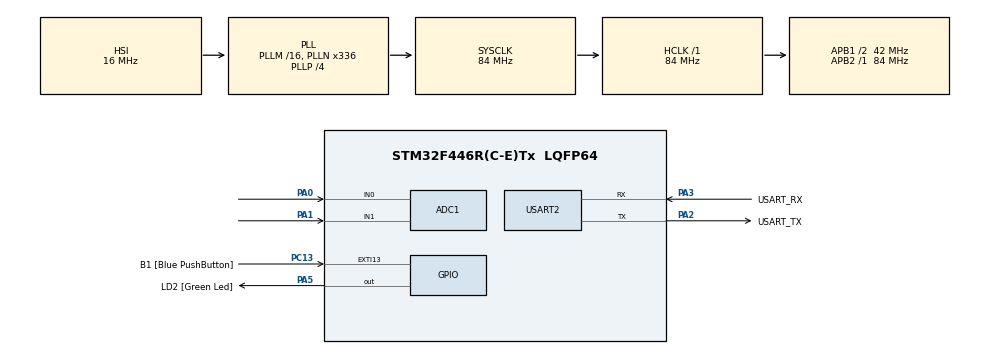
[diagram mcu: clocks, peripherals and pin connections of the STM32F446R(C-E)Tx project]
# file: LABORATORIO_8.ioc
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ADC1.Channel-0\#ChannelRegularConversion=ADC_CHANNEL_0
ADC1.Channel-1\#ChannelRegularConversion=ADC_CHANNEL_1
ADC1.ContinuousConvMode=ENABLE
ADC1.DMAContinuousRequests=ENABLE
ADC1.NbrOfConversion=2
ADC1.NbrOfConversionFlag=1
ADC1.Rank-0\#ChannelRegularConversion=1
ADC1.Rank-1\#ChannelRegularConversion=2
ADC1.SamplingTime-0\#ChannelRegularConversion=ADC_SAMPLETIME_3CYCLES
ADC1.SamplingTime-1\#ChannelRegularConversion=ADC_SAMPLETIME_3CYCLES
ADC1.ScanConvMode=ENABLE
ADC1.master=1
Dma.ADC1.0.Direction=DMA_PERIPH_TO_MEMORY
Dma.ADC1.0.FIFOMode=DMA_FIFOMODE_DISABLE
Dma.ADC1.0.Instance=DMA2_Stream0
Dma.ADC1.0.MemDataAlignment=DMA_MDATAALIGN_HALFWORD
Dma.ADC1.0.MemInc=DMA_MINC_ENABLE
Dma.ADC1.0.Mode=DMA_CIRCULAR
Dma.ADC1.0.PeriphDataAlignment=DMA_PDATAALIGN_HALFWORD
Dma.ADC1.0.PeriphInc=DMA_PINC_DISABLE
Dma.ADC1.0.Priority=DMA_PRIORITY_LOW
Dma.Request0=ADC1
Mcu.Family=STM32F4
Mcu.Name=STM32F446R(C-E)Tx
Mcu.Package=LQFP64
NVIC.ADC_IRQn=true\:0\:0\:false\:false\:true\:true\:true\:true
NVIC.DMA2_Stream0_IRQn=true\:0\:0\:false\:false\:true\:false\:true\:true
NVIC.PriorityGroup=NVIC_PRIORITYGROUP_0
NVIC.USART2_IRQn=true\:0\:0\:false\:false\:true\:true\:true\:true
PA0-WKUP.Signal=ADCx_IN0
PA1.Signal=ADCx_IN1
PA10.Signal=USART1_RX
PA13.GPIO_Label=TMS
PA13.Mode=Serial_Wire
PA13.Signal=SYS_JTMS-SWDIO
PA14.GPIO_Label=TCK
PA14.Mode=Serial_Wire
PA14.Signal=SYS_JTCK-SWCLK
PA2.GPIO_Label=USART_TX
PA2.Mode=Asynchronous
PA2.Signal=USART2_TX
PA3.GPIO_Label=USART_RX
PA3.Mode=Asynchronous
PA3.Signal=USART2_RX
PA5.GPIO_Label=LD2 [Green Led]
PA5.Signal=GPIO_Output
PA9.Signal=USART1_TX
PB3.GPIO_Label=SWO
PB3.Signal=SYS_JTDO-SWO
PC13.GPIO_Label=B1 [Blue PushButton]
PC13.GPIO_ModeDefaultEXTI=GPIO_MODE_IT_FALLING
PC13.Signal=GPXTI13
PC14-OSC32_IN.Mode=LSE-External-Oscillator
PC14-OSC32_IN.Signal=RCC_OSC32_IN
PC15-OSC32_OUT.Mode=LSE-External-Oscillator
PC15-OSC32_OUT.Signal=RCC_OSC32_OUT
PH0-OSC_IN.Mode=HSE-External-Oscillator
PH0-OSC_IN.Signal=RCC_OSC_IN
PH1-OSC_OUT.Mode=HSE-External-Oscillator
PH1-OSC_OUT.Signal=RCC_OSC_OUT
ProjectManager.HeapSize=0x200
ProjectManager.StackSize=0x400
ProjectManager.TargetToolchain=STM32CubeIDE
RCC.48MHZClocksFreq_Value=84000000
RCC.AHBFreq_Value=84000000
RCC.APB1CLKDivider=RCC_HCLK_DIV2
RCC.APB1Freq_Value=42000000
RCC.APB1TimFreq_Value=84000000
RCC.APB2Freq_Value=84000000
RCC.APB2TimFreq_Value=84000000
RCC.CortexFreq_Value=84000000
RCC.FLatency-AdvancedSettings=FLASH_LATENCY_2
RCC.HCLKFreq_Value=84000000
RCC.HSE_VALUE=8000000
RCC.HSI_VALUE=16000000
RCC.PLLN=336
RCC.PLLP=RCC_PLLP_DIV4
RCC.SYSCLKFreq_VALUE=84000000
RCC.SYSCLKSource=RCC_SYSCLKSOURCE_PLLCLK
RCC.USBFreq_Value=168000000
RCC.VCOOutputFreq_Value=336000000
SH.ADCx_IN0.0=ADC1_IN0,IN0
SH.ADCx_IN1.0=ADC1_IN1,IN1
USART2.VirtualMode=VM_ASYNC
board=NUCLEO-F446RE

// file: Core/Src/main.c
/* USER CODE BEGIN Header */
/**
  ******************************************************************************
  * @file           : main.c
  * @brief          : LABORATORIO 8 - Joystick Funcional
  ******************************************************************************
  */
/* USER CODE END Header */
#include "main.h"
#include <stdio.h>

/* Variables de Hardware */
ADC_HandleTypeDef hadc1;
UART_HandleTypeDef huart2;
DMA_HandleTypeDef hdma_adc1; // Variable fantasma para evitar errores de linker

/* USER CODE BEGIN PV */
volatile uint16_t ADC_VALOR[2] = {2048, 2048};
volatile uint8_t  canal_actual = 0;
/* USER CODE END PV */

/* Prototipos */
void SystemClock_Config(void);
static void MX_GPIO_Init(void);
static void MX_ADC1_Init(void);
static void MX_USART2_UART_Init(void);

/* Redireccion de printf */
int _write(int file, char *ptr, int len) {
    HAL_UART_Transmit(&huart2, (uint8_t*)ptr, len, HAL_MAX_DELAY);
    return len;
}

/**
  * @brief Callback de Interrupción: Guarda PA0 y luego PA1
  */
void HAL_ADC_ConvCpltCallback(ADC_HandleTypeDef* hadc) {
    if(hadc->Instance == ADC1) {
        ADC_VALOR[canal_actual] = HAL_ADC_GetValue(hadc);
        canal_actual = (canal_actual == 0) ? 1 : 0;
    }
}

int main(void) {
    HAL_Init();
    SystemClock_Config();
    MX_GPIO_Init();
    MX_ADC1_Init();
    MX_USART2_UART_Init();

    setbuf(stdout, NULL);
    HAL_Delay(500);
    printf("\r\n--- JOYSTICK LISTO (Umbrales Ajustados) ---\r\n");

    // Iniciar el ciclo de interrupciones
    HAL_ADC_Start_IT(&hadc1);

    while (1) {
        HAL_GPIO_TogglePin(GPIOA, GPIO_PIN_5);

        // --- LOGICA DE LABORATORIO CON ZONA MUERTA ---
        // Solo imprime si se aleja significativamente del centro (2048)

        // EJE VERTICAL (PA0)
        if (ADC_VALOR[0] > 3000)      printf("ARRIBA\r\n");
        else if (ADC_VALOR[0] < 1000) printf("ABAJO\r\n");

        // EJE HORIZONTAL (PA1)
        if (ADC_VALOR[1] > 3000)      printf("DERECHA\r\n");
        else if (ADC_VALOR[1] < 1000) printf("IZQUIERDA\r\n");

        // Disparar la siguiente ráfaga de conversión
        HAL_ADC_Start_IT(&hadc1);

        HAL_Delay(200); // Delay para no saturar la terminal
    }
}

/* --- CONFIGURACION DEL ADC --- */

static void MX_ADC1_Init(void) {
    ADC_ChannelConfTypeDef sConfig = {0};
    hadc1.Instance = ADC1;
    hadc1.Init.ClockPrescaler = ADC_CLOCK_SYNC_PCLK_DIV4;
    hadc1.Init.Resolution = ADC_RESOLUTION_12B;
    hadc1.Init.ScanConvMode = ENABLE;           // Escaneo de 2 canales
    hadc1.Init.ContinuousConvMode = DISABLE;
    hadc1.Init.DiscontinuousConvMode = DISABLE;
    hadc1.Init.ExternalTrigConvEdge = ADC_EXTERNALTRIGCONVEDGE_NONE;
    hadc1.Init.ExternalTrigConv = ADC_SOFTWARE_START;
    hadc1.Init.DataAlign = ADC_DATAALIGN_RIGHT;
    hadc1.Init.NbrOfConversion = 2;             // Importante: 2 canales
    hadc1.Init.DMAContinuousRequests = DISABLE;
    hadc1.Init.EOCSelection = ADC_EOC_SINGLE_CONV;
    HAL_ADC_Init(&hadc1);

    // Canal 0 - PA0
    sConfig.Channel = ADC_CHANNEL_0;
    sConfig.Rank = 1;
    sConfig.SamplingTime = ADC_SAMPLETIME_15CYCLES;
    HAL_ADC_ConfigChannel(&hadc1, &sConfig);

    // Canal 1 - PA1
    sConfig.Channel = ADC_CHANNEL_1;
    sConfig.Rank = 2;
    HAL_ADC_ConfigChannel(&hadc1, &sConfig);
}

/* ... Resto de funciones (UART2, GPIO, Clock) se mantienen igual ... */

static void MX_USART2_UART_Init(void) {
    huart2.Instance = USART2;
    huart2.Init.BaudRate = 115200;
    huart2.Init.WordLength = UART_WORDLENGTH_8B;
    huart2.Init.StopBits = UART_STOPBITS_1;
    huart2.Init.Parity = UART_PARITY_NONE;
    huart2.Init.Mode = UART_MODE_TX_RX;
    huart2.Init.HwFlowCtl = UART_HWCONTROL_NONE;
    huart2.Init.OverSampling = UART_OVERSAMPLING_16;
    HAL_UART_Init(&huart2);
}

static void MX_GPIO_Init(void) {
    __HAL_RCC_GPIOA_CLK_ENABLE();
    GPIO_InitTypeDef GPIO_InitStruct = {0};
    GPIO_InitStruct.Pin = GPIO_PIN_5;
    GPIO_InitStruct.Mode = GPIO_MODE_OUTPUT_PP;
    GPIO_InitStruct.Pull = GPIO_NOPULL;
    GPIO_InitStruct.Speed = GPIO_SPEED_FREQ_LOW;
    HAL_GPIO_Init(GPIOA, &GPIO_InitStruct);
}

void SystemClock_Config(void) {
    RCC_OscInitTypeDef RCC_OscInitStruct = {0};
    RCC_ClkInitTypeDef RCC_ClkInitStruct = {0};
    __HAL_RCC_PWR_CLK_ENABLE();
    __HAL_PWR_VOLTAGESCALING_CONFIG(PWR_REGULATOR_VOLTAGE_SCALE3);
    RCC_OscInitStruct.OscillatorType = RCC_OSCILLATORTYPE_HSI;
    RCC_OscInitStruct.HSIState = RCC_HSI_ON;
    RCC_OscInitStruct.HSICalibrationValue = RCC_HSICALIBRATION_DEFAULT;
    RCC_OscInitStruct.PLL.PLLState = RCC_PLL_ON;
    RCC_OscInitStruct.PLL.PLLSource = RCC_PLLSOURCE_HSI;
    RCC_OscInitStruct.PLL.PLLM = 16;
    RCC_OscInitStruct.PLL.PLLN = 336;
    RCC_OscInitStruct.PLL.PLLP = RCC_PLLP_DIV4;
    RCC_OscInitStruct.PLL.PLLQ = 2;
    RCC_OscInitStruct.PLL.PLLR = 2;
    HAL_RCC_OscConfig(&RCC_OscInitStruct);
    RCC_ClkInitStruct.ClockType = RCC_CLOCKTYPE_HCLK|RCC_CLOCKTYPE_SYSCLK|RCC_CLOCKTYPE_PCLK1|RCC_CLOCKTYPE_PCLK2;
    RCC_ClkInitStruct.SYSCLKSource = RCC_SYSCLKSOURCE_PLLCLK;
    RCC_ClkInitStruct.AHBCLKDivider = RCC_SYSCLK_DIV1;
    RCC_ClkInitStruct.APB1CLKDivider = RCC_HCLK_DIV2;
    RCC_ClkInitStruct.APB2CLKDivider = RCC_HCLK_DIV1;
    HAL_RCC_ClockConfig(&RCC_ClkInitStruct, FLASH_LATENCY_2);
}

void Error_Handler(void) { __disable_irq(); while (1) {} }
